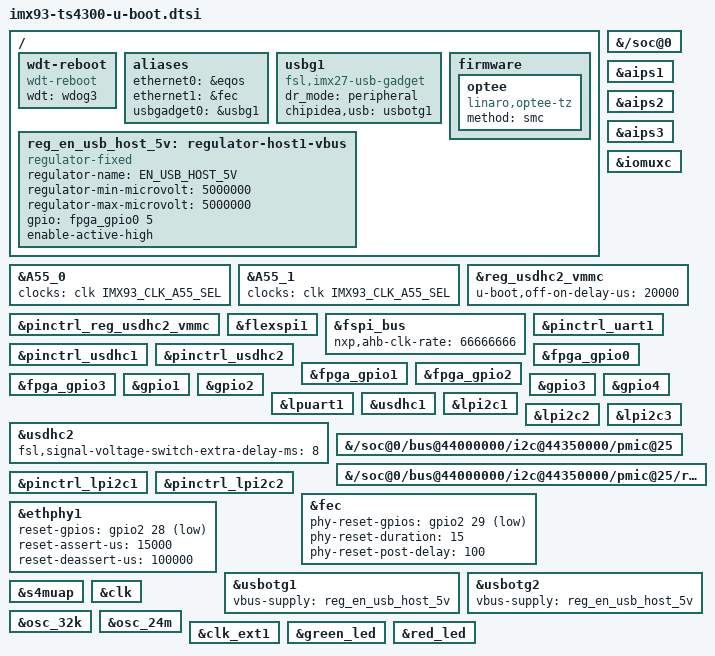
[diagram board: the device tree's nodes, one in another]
// SPDX-License-Identifier: GPL-2.0+
/*
 * Copyright 2022 NXP
 */

#include "imx93-u-boot.dtsi"

/ {
	wdt-reboot {
		compatible = "wdt-reboot";
		wdt = <&wdog3>;
		bootph-pre-ram;
		bootph-some-ram;
	};

	aliases {
		ethernet0 = &eqos;
		ethernet1 = &fec;
		usbgadget0 = &usbg1;
	};

	usbg1: usbg1 {
		compatible = "fsl,imx27-usb-gadget";
		dr_mode = "peripheral";
		chipidea,usb = <&usbotg1>;
		status = "okay";
	};

	firmware {
		optee {
			compatible = "linaro,optee-tz";
			method = "smc";
		};
	};

	reg_en_usb_host_5v: regulator-host1-vbus {
		compatible = "regulator-fixed";
		regulator-name = "EN_USB_HOST_5V";
		regulator-min-microvolt = <5000000>;
		regulator-max-microvolt = <5000000>;
		gpio = <&fpga_gpio0 5 GPIO_ACTIVE_HIGH>;
		enable-active-high;
	};
};

&A55_0 {
	clocks = <&clk IMX93_CLK_A55_SEL>;
};

&A55_1 {
	clocks = <&clk IMX93_CLK_A55_SEL>;
};

&{/soc@0} {
	bootph-all;
	bootph-pre-ram;
};

&aips1 {
	bootph-pre-ram;
	bootph-all;
};

&aips2 {
	bootph-pre-ram;
	bootph-some-ram;
};

&aips3 {
	bootph-pre-ram;
	bootph-some-ram;
};

&iomuxc {
	bootph-pre-ram;
	bootph-some-ram;
};

&reg_usdhc2_vmmc {
	u-boot,off-on-delay-us = <20000>;
	bootph-pre-ram;
};

&pinctrl_reg_usdhc2_vmmc {
	bootph-pre-ram;
};

&flexspi1 {
	bootph-pre-ram;
};

&fspi_bus {
	bootph-pre-ram;
	bootph-some-ram;
	nxp,ahb-clk-rate = <66666666>;
};

&pinctrl_uart1 {
	bootph-pre-ram;
	bootph-some-ram;
};

&pinctrl_usdhc1 {
	bootph-pre-ram;
};

&pinctrl_usdhc2 {
	bootph-pre-ram;
};

&fpga_gpio0 {
	bootph-some-ram;
};

&fpga_gpio1 {
	bootph-some-ram;
};

&fpga_gpio2 {
	bootph-some-ram;
};

&fpga_gpio3 {
	bootph-some-ram;
};

&gpio1 {
	bootph-pre-ram;
	bootph-some-ram;
};

&gpio2 {
	bootph-pre-ram;
	bootph-some-ram;
};

&gpio3 {
	bootph-pre-ram;
	bootph-some-ram;
};

&gpio4 {
	bootph-pre-ram;
	bootph-some-ram;
};

&lpuart1 {
	bootph-pre-ram;
	bootph-some-ram;
};

&usdhc1 {
	bootph-pre-ram;
};

&usdhc2 {
	bootph-pre-ram;
	fsl,signal-voltage-switch-extra-delay-ms = <8>;
};

&lpi2c1 {
	bootph-pre-ram;
};

&lpi2c2 {
	bootph-pre-ram;
};

&lpi2c3 {
	bootph-pre-ram;
};

&{/soc@0/bus@44000000/i2c@44350000/pmic@25} {
	bootph-pre-ram;
};

&{/soc@0/bus@44000000/i2c@44350000/pmic@25/regulators} {
	bootph-pre-ram;
};

&pinctrl_lpi2c1 {
	bootph-pre-ram;
};

&pinctrl_lpi2c2 {
	bootph-pre-ram;
};

/* ETH2_RESET# is passed through the FPGA to GPIO_19 */
&fec {
	phy-reset-gpios = <&gpio2 29 GPIO_ACTIVE_LOW>;
	phy-reset-duration = <15>;
	phy-reset-post-delay = <100>;
};

/* ETH1_RESET# is passed through the FPGA to GPIO_20 */
&ethphy1 {
	reset-gpios = <&gpio2 28 GPIO_ACTIVE_LOW>;
	reset-assert-us = <15000>;
	reset-deassert-us = <100000>;
};

&usbotg1 {
	status = "okay";
	vbus-supply = <&reg_en_usb_host_5v>;
};

&usbotg2 {
	status = "okay";
	vbus-supply = <&reg_en_usb_host_5v>;
};

&s4muap {
	bootph-pre-ram;
	bootph-some-ram;
	status = "okay";
};

&clk {
	bootph-all;
	bootph-pre-ram;
	/delete-property/ assigned-clocks;
	/delete-property/ assigned-clock-rates;
	/delete-property/ assigned-clock-parents;
};

&osc_32k {
	bootph-all;
	bootph-pre-ram;
};

&osc_24m {
	bootph-all;
	bootph-pre-ram;
};

&clk_ext1 {
	bootph-all;
	bootph-pre-ram;
};

/* We need to use these LED GPIO first for bbdetect. Remove the default state
 * from the DTS, and we will set it manually in board late init. */
&green_led {
	/delete-property/ default-state;
};

&red_led {
	/delete-property/ default-state;
};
